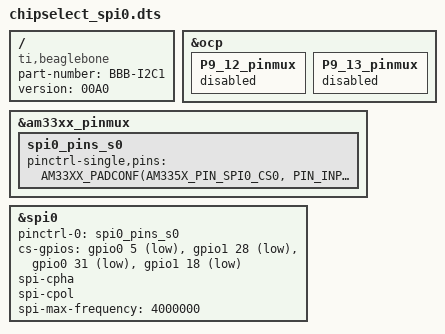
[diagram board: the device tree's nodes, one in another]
/dts-v1/;
/plugin/;

#include <dt-bindings/pinctrl/omap.h>
#include <dt-bindings/pinctrl/am33xx.h>
#include <dt-bindings/interrupt-controller/irq.h>
#include <dt-bindings/gpio/gpio.h>

/{ /* this is our device tree overlay root node */

	compatible = "ti,beaglebone", "ti,beaglebone-black";
	part-number = "BBB-I2C1"; // you can choose any name here but it should be memorable
 	version = "00A0";

	fragment@0 {
		target = <&ocp>;

		__overlay__ {
			P9_12_pinmux { status = "disabled"; };
			P9_13_pinmux { status = "disabled"; };
		};

	};
    fragment@1 {
        target = <&am33xx_pinmux>;
        __overlay__ {
            spi0_pins_s0: spi0_pins_s0 {
			pinctrl-single,pins = <
				AM33XX_PADCONF(AM335X_PIN_SPI0_CS0, PIN_INPUT_PULLUP, MUX_MODE0)
				AM33XX_PADCONF(AM335X_PIN_SPI0_D0, PIN_INPUT_PULLUP, MUX_MODE0)
				AM33XX_PADCONF(AM335X_PIN_SPI0_D1, PIN_OUTPUT_PULLUP, MUX_MODE0)
				AM33XX_PADCONF(AM335X_PIN_SPI0_SCLK, PIN_INPUT_PULLUP, MUX_MODE0)
				AM33XX_PADCONF(AM335X_PIN_GPMC_BEN1, PIN_INPUT_PULLUP, MUX_MODE7)	/* P9 pin 12 */
				AM33XX_PADCONF(AM335X_PIN_GPMC_WPN, PIN_INPUT_PULLUP, MUX_MODE7)	/* P9 pin 13 */
				AM33XX_PADCONF(AM335X_PIN_GPMC_A2, PIN_INPUT_PULLUP, MUX_MODE7)		/* P9 pin 14 */
				>;
            };
        };
    };
	fragment@2 {
		target = <&spi0>;
		__overlay__ {
			#address-cells = <1>;
			#size-cells = <0>;
			status = "okay";
			pinctrl-names = "default";
			pinctrl-0 = <&spi0_pins_s0>;
			cs-gpios = <&gpio0 5 GPIO_ACTIVE_LOW>, <&gpio1 28 GPIO_ACTIVE_LOW>, <&gpio0 31 GPIO_ACTIVE_LOW>, <&gpio1 18 GPIO_ACTIVE_LOW>;  /* CS0=P9 pin17, CS1=P9 pin 12, CS2=P9 pin 13, CS3=P9 pin 14 */
			spi-cpha;
			spi-cpol;
			spi-max-frequency = <4000000>;
		};
	};
}; /* root node end */
